# MLDR187 register map
File version: 1.4
CPU: MDR32F02, little endian
Registers are 32-bit, read-write, no defined reset value unless marked. A register's access mark holds for its fields unless they carry their own. Offsets are from the block's base; [hi:lo] are bit positions.

## UART1 — UART1 description
Base 0x40008000
Same registers: UART2 0x40010000, UART3 0x40038000, UART4 0x400E8000
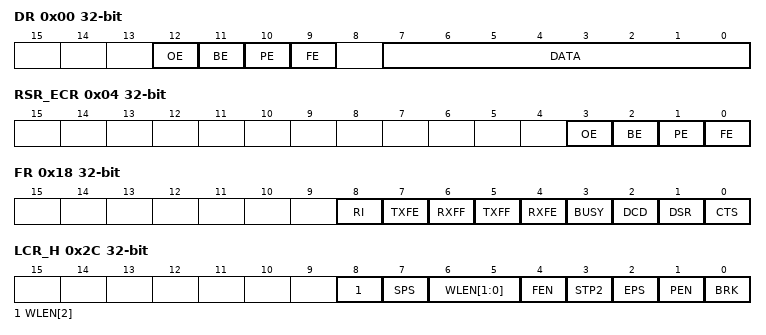
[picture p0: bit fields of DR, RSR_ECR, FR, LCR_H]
0x00 DR — DR description
  [12] OE — OE description
  [11] BE — BE description
  [10] PE — PE description
  [9] FE — FE description
  [7:0] DATA — DATA description
0x04 RSR_ECR — RSR_ECR description
  [3] OE — OE description
  [2] BE — BE description
  [1] PE — PE description
  [0] FE — FE description
0x18 FR — FR description
  [8] RI — RI description
  [7] TXFE — TXFE description
  [6] RXFF — RXFF description
  [5] TXFF — TXFF description
  [4] RXFE — RXFE description
  [3] BUSY — BUSY description
  [2] DCD — DCD description
  [1] DSR — DSR description
  [0] CTS — CTS description
0x20 ILPR — ILPR description
  [7:0] DVSR — DVSR description
0x24 IBRD — IBRD description
  [15:0] BAUDDIV_INT — BAUDDIV_INT description
0x28 FBRD — FBRD description
  [5:0] BAUDDIV_FRAC — BAUDDIV_FRAC description
0x2C LCR_H — LCR_H description
  [8] WLEN[2] — WLEN[2] description
  [7] SPS — SPS description
  [6:5] WLEN[1:0] — WLEN[1:0] description
  [4] FEN — FEN description
  [3] STP2 — STP2 description
  [2] EPS — EPS description
  [1] PEN — PEN description
  [0] BRK — BRK description
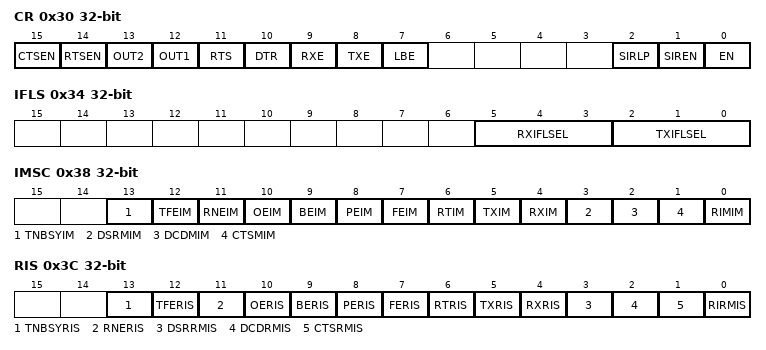
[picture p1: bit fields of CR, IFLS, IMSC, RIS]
0x30 CR — CR description
  [15] CTSEN — CTSEN description
  [14] RTSEN — RTSEN description
  [13] OUT2 — OUT2 description
  [12] OUT1 — OUT1 description
  [11] RTS — RTS description
  [10] DTR — DTR description
  [9] RXE — RXE description
  [8] TXE — TXE description
  [7] LBE — LBE description
  [2] SIRLP — SIRLP description
  [1] SIREN — SIREN description
  [0] EN — EN description
0x34 IFLS — IFLS description
  [5:3] RXIFLSEL — RXIFLSEL description
  [2:0] TXIFLSEL — TXIFLSEL description
0x38 IMSC — IMSC description
  [13] TNBSYIM — TNBSYIM description
  [12] TFEIM — TFEIM description
  [11] RNEIM — RNEIM description
  [10] OEIM — OEIM description
  [9] BEIM — BEIM description
  [8] PEIM — PEIM description
  [7] FEIM — FEIM description
  [6] RTIM — RTIM description
  [5] TXIM — TXIM description
  [4] RXIM — RXIM description
  [3] DSRMIM — DSRMIM description
  [2] DCDMIM — DCDMIM description
  [1] CTSMIM — CTSMIM description
  [0] RIMIM — RIMIM description
0x3C RIS — RIS description
  [13] TNBSYRIS — TNBSYRIS description
  [12] TFERIS — TFERIS description
  [11] RNERIS — RNERIS description
  [10] OERIS — OERIS description
  [9] BERIS — BERIS description
  [8] PERIS — PERIS description
  [7] FERIS — FERIS description
  [6] RTRIS — RTRIS description
  [5] TXRIS — TXRIS description
  [4] RXRIS — RXRIS description
  [3] DSRRMIS — DSRRMIS description
  [2] DCDRMIS — DCDRMIS description
  [1] CTSRMIS — CTSRMIS description
  [0] RIRMIS — RIRMIS description
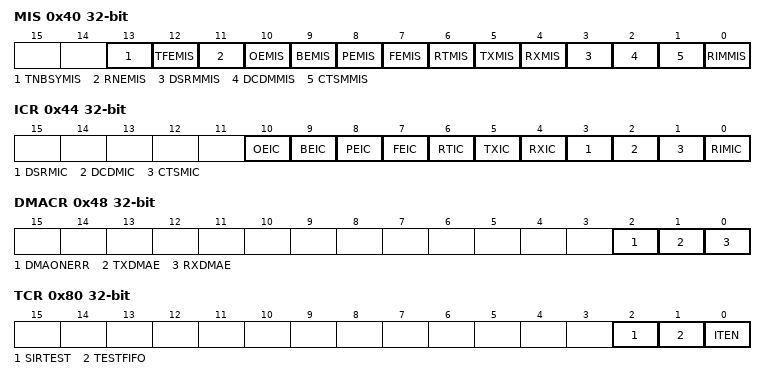
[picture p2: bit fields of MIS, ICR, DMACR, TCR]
0x40 MIS — MIS description
  [13] TNBSYMIS — TNBSYMIS description
  [12] TFEMIS — TFEMIS description
  [11] RNEMIS — RNEMIS description
  [10] OEMIS — OEMIS description
  [9] BEMIS — BEMIS description
  [8] PEMIS — PEMIS description
  [7] FEMIS — FEMIS description
  [6] RTMIS — RTMIS description
  [5] TXMIS — TXMIS description
  [4] RXMIS — RXMIS description
  [3] DSRMMIS — DSRMMIS description
  [2] DCDMMIS — DCDMMIS description
  [1] CTSMMIS — CTSMMIS description
  [0] RIMMIS — RIMMIS description
0x44 ICR — ICR description
  [10] OEIC — OEIC description
  [9] BEIC — BEIC description
  [8] PEIC — PEIC description
  [7] FEIC — FEIC description
  [6] RTIC — RTIC description
  [5] TXIC — TXIC description
  [4] RXIC — RXIC description
  [3] DSRMIC — DSRMIC description
  [2] DCDMIC — DCDMIC description
  [1] CTSMIC — CTSMIC description
  [0] RIMIC — RIMIC description
0x48 DMACR — DMACR description
  [2] DMAONERR — DMAONERR description
  [1] TXDMAE — TXDMAE description
  [0] RXDMAE — RXDMAE description
0x80 TCR — TCR description
  [2] SIRTEST — SIRTEST description
  [1] TESTFIFO — TESTFIFO description
  [0] ITEN — ITEN description
